AUTOSAR XML (schema 3.1.2)
package /Components/SWC_PFilFast
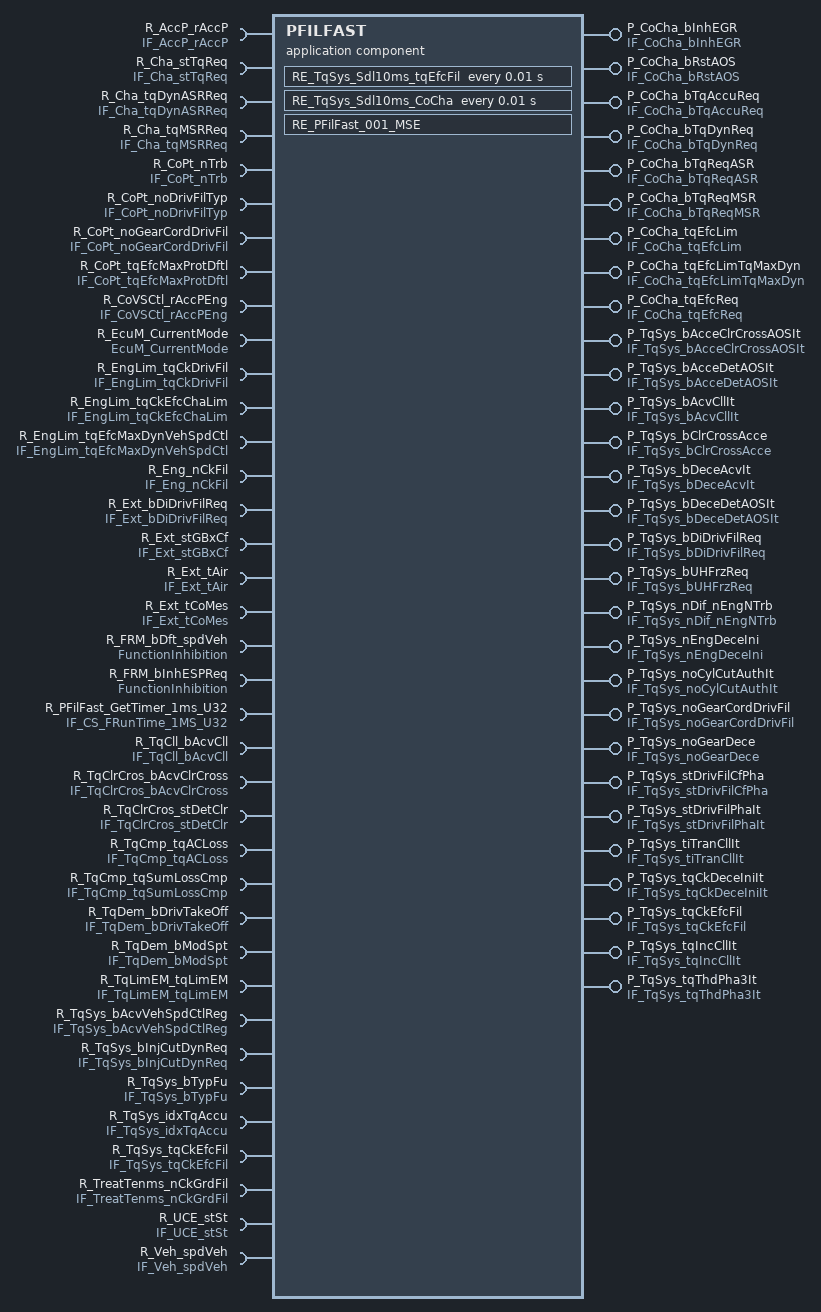
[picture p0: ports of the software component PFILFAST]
  application software component type PFILFAST  # PFilFast
    29 x provide port:
      P_CoCha_bInhEGR: unqueued-sender-com-spec{data-element=CoCha_bInhEGR, can-invalidate=false, init-value=ConstantValue}, provided-interface=IF_CoCha_bInhEGR  # Requirement: 01552_10_01267-PFilFast.I148(0)
      P_CoCha_bRstAOS: unqueued-sender-com-spec{data-element=CoCha_bRstAOS, can-invalidate=false, init-value=ConstantValue1}, provided-interface=IF_CoCha_bRstAOS  # Requirement: 01552_10_01267-PFilFast.I149(0)
      P_CoCha_bTqAccuReq: unqueued-sender-com-spec{data-element=CoCha_bTqAccuReq, can-invalidate=false, init-value=ConstantValue3}, provided-interface=IF_CoCha_bTqAccuReq  # Requirement: 01552_10_01267-PFilFast.I150(0)
      P_CoCha_bTqDynReq: unqueued-sender-com-spec{data-element=CoCha_bTqDynReq, can-invalidate=false, init-value=ConstantValue5}, provided-interface=IF_CoCha_bTqDynReq  # Requirement: 01552_10_01267-PFilFast.I151(0)
      P_CoCha_bTqReqASR: unqueued-sender-com-spec{data-element=CoCha_bTqReqASR, can-invalidate=false, init-value=ConstantValue7}, provided-interface=IF_CoCha_bTqReqASR  # Requirement: 01552_10_01267-PFilFast.I152(0)
      P_CoCha_bTqReqMSR: unqueued-sender-com-spec{data-element=CoCha_bTqReqMSR, can-invalidate=false, init-value=ConstantValue9}, provided-interface=IF_CoCha_bTqReqMSR  # Requirement: 01552_10_01267-PFilFast.I153(0)
      P_CoCha_tqEfcLim: unqueued-sender-com-spec{data-element=CoCha_tqEfcLim, can-invalidate=false, init-value=ConstantValue11}, provided-interface=IF_CoCha_tqEfcLim  # Requirement: 01552_10_01267-PFilFast.I154(0)
      P_CoCha_tqEfcLimTqMaxDyn: unqueued-sender-com-spec{data-element=CoCha_tqEfcLimTqMaxDyn, can-invalidate=false, init-value=ConstantValue13}, provided-interface=IF_CoCha_tqEfcLimTqMaxDyn  # Requirement: 01552_10_01267-PFilFast.I146(0)
      P_CoCha_tqEfcReq: unqueued-sender-com-spec{data-element=CoCha_tqEfcReq, can-invalidate=false, init-value=ConstantValue15}, provided-interface=IF_CoCha_tqEfcReq  # Requirement: 01552_10_01267-PFilFast.I147(0)
      P_TqSys_bAcceClrCrossAOSIt: unqueued-sender-com-spec{data-element=TqSys_bAcceClrCrossAOSIt, can-invalidate=false, init-value=ConstantValue17}, provided-interface=IF_TqSys_bAcceClrCrossAOSIt  # Requirement: 01552_10_01267-PFilFast.I102(0)
      P_TqSys_bAcceDetAOSIt: unqueued-sender-com-spec{data-element=TqSys_bAcceDetAOSIt, can-invalidate=false, init-value=ConstantValue19}, provided-interface=IF_TqSys_bAcceDetAOSIt  # Requirement: 01552_10_01267-PFilFast.I103(0)
      P_TqSys_bAcvCllIt: unqueued-sender-com-spec{data-element=TqSys_bAcvCllIt, can-invalidate=false, init-value=ConstantValue21}, provided-interface=IF_TqSys_bAcvCllIt  # Requirement: 01552_10_01267-PFilFast.I104(0)
      P_TqSys_bClrCrossAcce: unqueued-sender-com-spec{data-element=TqSys_bClrCrossAcce, can-invalidate=false, init-value=ConstantValue23}, provided-interface=IF_TqSys_bClrCrossAcce  # Requirement: 01552_10_01267-PFilFast.I105(0)
      P_TqSys_bDeceAcvIt: unqueued-sender-com-spec{data-element=TqSys_bDeceAcvIt, can-invalidate=false, init-value=ConstantValue25}, provided-interface=IF_TqSys_bDeceAcvIt  # Requirement: 01552_10_01267-PFilFast.I106(0)
      P_TqSys_bDeceDetAOSIt: unqueued-sender-com-spec{data-element=TqSys_bDeceDetAOSIt, can-invalidate=false, init-value=ConstantValue27}, provided-interface=IF_TqSys_bDeceDetAOSIt  # Requirement: 01552_10_01267-PFilFast.I107(0)
      P_TqSys_bDiDrivFilReq: unqueued-sender-com-spec{data-element=TqSys_bDiDrivFilReq, can-invalidate=false, init-value=ConstantValue29}, provided-interface=IF_TqSys_bDiDrivFilReq  # Requirement: 01552_10_01267-PFilFast.I100(0)
      P_TqSys_bUHFrzReq: unqueued-sender-com-spec{data-element=TqSys_bUHFrzReq, can-invalidate=false, init-value=ConstantValue31}, provided-interface=IF_TqSys_bUHFrzReq  # Requirement: 01552_10_01267-PFilFast.I108(0)
      P_TqSys_nDif_nEngNTrb: unqueued-sender-com-spec{data-element=TqSys_nDif_nEngNTrb, can-invalidate=false, init-value=ConstantValue33}, provided-interface=IF_TqSys_nDif_nEngNTrb  # Requirement: 01552_10_01267-PFilFast.I109(0)
      P_TqSys_nEngDeceIni: unqueued-sender-com-spec{data-element=TqSys_nEngDeceIni, can-invalidate=false, init-value=ConstantValue35}, provided-interface=IF_TqSys_nEngDeceIni  # Requirement: 01552_10_01267-PFilFast.I101(0)
      P_TqSys_noCylCutAuthIt: unqueued-sender-com-spec{data-element=TqSys_noCylCutAuthIt, can-invalidate=false, init-value=ConstantValue37}, provided-interface=IF_TqSys_noCylCutAuthIt  # Requirement: 01552_10_01267-PFilFast.I110(0)
      P_TqSys_noGearCordDrivFil: unqueued-sender-com-spec{data-element=TqSys_noGearCordDrivFil, can-invalidate=false, init-value=ConstantValue39}, provided-interface=IF_TqSys_noGearCordDrivFil  # Requirement: 01552_10_01267-PFilFast.I111(0)
      P_TqSys_noGearDece: unqueued-sender-com-spec{data-element=TqSys_noGearDece, can-invalidate=false, init-value=ConstantValue41}, provided-interface=IF_TqSys_noGearDece  # Requirement: 01552_10_01267-PFilFast.I112(0)
      P_TqSys_stDrivFilCfPha: unqueued-sender-com-spec{data-element=TqSys_stDrivFilCfPha, can-invalidate=false, init-value=ConstantValue43}, provided-interface=IF_TqSys_stDrivFilCfPha  # Requirement: 01552_10_01267-PFilFast.I113(0)
      P_TqSys_stDrivFilPhaIt: unqueued-sender-com-spec{data-element=TqSys_stDrivFilPhaIt, can-invalidate=false, init-value=ConstantValue45}, provided-interface=IF_TqSys_stDrivFilPhaIt  # Requirement: 01552_10_01267-PFilFast.I114(0)
      P_TqSys_tiTranCllIt: unqueued-sender-com-spec{data-element=TqSys_tiTranCllIt, can-invalidate=false, init-value=ConstantValue47}, provided-interface=IF_TqSys_tiTranCllIt  # Requirement: 01552_10_01267-PFilFast.I115(0)
      P_TqSys_tqCkDeceIniIt: unqueued-sender-com-spec{data-element=TqSys_tqCkDeceIniIt, can-invalidate=false, init-value=ConstantValue49}, provided-interface=IF_TqSys_tqCkDeceIniIt  # Requirement: 01552_10_01267-PFilFast.I116(0)
      P_TqSys_tqCkEfcFil: unqueued-sender-com-spec{data-element=TqSys_tqCkEfcFil, can-invalidate=false, init-value=ConstantValue51}, provided-interface=IF_TqSys_tqCkEfcFil  # Requirement: 01552_10_01267-PFilFast.I117(0)
      P_TqSys_tqIncCllIt: unqueued-sender-com-spec{data-element=TqSys_tqIncCllIt, can-invalidate=false, init-value=ConstantValue53}, provided-interface=IF_TqSys_tqIncCllIt  # Requirement: 01552_10_01267-PFilFast.I118(0)
      P_TqSys_tqThdPha3It: unqueued-sender-com-spec{data-element=TqSys_tqThdPha3It, can-invalidate=false, init-value=ConstantValue55}, provided-interface=IF_TqSys_tqThdPha3It  # Requirement: 01552_10_01267-PFilFast.I119(0)
    37 x require port:
      R_AccP_rAccP: unqueued-receiver-com-spec{data-element=AccP_rAccP, init-value=ConstantValue57, resync-time=0}, required-interface=IF_AccP_rAccP  # Requirement: 01552_10_01267-PFilFast.I120(0)
      R_Cha_stTqReq: unqueued-receiver-com-spec{data-element=Cha_stTqReq, init-value=ConstantValue59, resync-time=0}, required-interface=IF_Cha_stTqReq  # Requirement: 01552_10_01267-PFilFast.I155(0)
      R_Cha_tqDynASRReq: unqueued-receiver-com-spec{data-element=Cha_tqDynASRReq, init-value=ConstantValue61, resync-time=0}, required-interface=IF_Cha_tqDynASRReq  # Requirement: 01552_10_01267-PFilFast.I121(0)
      R_Cha_tqMSRReq: unqueued-receiver-com-spec{data-element=Cha_tqMSRReq, init-value=ConstantValue63, resync-time=0}, required-interface=IF_Cha_tqMSRReq  # Requirement: 01552_10_01267-PFilFast.I156(0)
      R_CoPt_nTrb: unqueued-receiver-com-spec{data-element=CoPt_nTrb, init-value=ConstantValue65, resync-time=0}, required-interface=IF_CoPt_nTrb  # Requirement: 01552_10_01267-PFilFast.I124(0)
      R_CoPt_noDrivFilTyp: unqueued-receiver-com-spec{data-element=CoPt_noDrivFilTyp, init-value=ConstantValue67, resync-time=0}, required-interface=IF_CoPt_noDrivFilTyp  # Requirement: 01552_10_01267-PFilFast.I122(0)
      R_CoPt_noGearCordDrivFil: unqueued-receiver-com-spec{data-element=CoPt_noGearCordDrivFil, init-value=ConstantValue69, resync-time=0}, required-interface=IF_CoPt_noGearCordDrivFil  # Requirement: 01552_10_01267-PFilFast.I123(0)
      R_CoPt_tqEfcMaxProtDftl: unqueued-receiver-com-spec{data-element=CoPt_tqEfcMaxProtDftl, init-value=ConstantValue71, resync-time=0}, required-interface=IF_CoPt_tqEfcMaxProtDftl  # Requirement: 01552_10_01267-PFilFast.I157(0)
      R_CoVSCtl_rAccPEng: unqueued-receiver-com-spec{data-element=CoVSCtl_rAccPEng, init-value=ConstantValue73, resync-time=0}, required-interface=IF_CoVSCtl_rAccPEng  # Requirement: 01552_10_01267-PFilFast.I125(0)
      R_EcuM_CurrentMode: required-interface=EcuM_CurrentMode  # Requirement: 01552_09_00532-SSTG-C007(0)
      R_EngLim_tqCkDrivFil: unqueued-receiver-com-spec{data-element=EngLim_tqCkDrivFil, init-value=ConstantValue75, resync-time=0}, required-interface=IF_EngLim_tqCkDrivFil  # Requirement: 01552_10_01267-PFilFast.I127(0)
      R_EngLim_tqCkEfcChaLim: unqueued-receiver-com-spec{data-element=EngLim_tqCkEfcChaLim, init-value=ConstantValue77, resync-time=0}, required-interface=IF_EngLim_tqCkEfcChaLim  # Requirement: 01552_10_01267-PFilFast.I158(0)
      R_EngLim_tqEfcMaxDynVehSpdCtl: unqueued-receiver-com-spec{data-element=EngLim_tqEfcMaxDynVehSpdCtl, init-value=ConstantValue79, resync-time=0}, required-interface=IF_EngLim_tqEfcMaxDynVehSpdCtl  # Requirement: 01552_10_01267-PFilFast.I159(0)
      R_Eng_nCkFil: unqueued-receiver-com-spec{data-element=Eng_nCkFil, init-value=ConstantValue81, resync-time=0}, required-interface=IF_Eng_nCkFil  # Requirement: 01552_10_01267-PFilFast.I126(0)
      R_Ext_bDiDrivFilReq: unqueued-receiver-com-spec{data-element=Ext_bDiDrivFilReq, init-value=ConstantValue83, resync-time=0}, required-interface=IF_Ext_bDiDrivFilReq  # Requirement: 01552_10_01267-PFilFast.I128(0)
      R_Ext_stGBxCf: unqueued-receiver-com-spec{data-element=Ext_stGBxCf, init-value=ConstantValue85, resync-time=0}, required-interface=IF_Ext_stGBxCf  # Requirement: 01552_10_01267-PFilFast.I129(0)
      R_Ext_tAir: unqueued-receiver-com-spec{data-element=Ext_tAir, init-value=ConstantValue87, resync-time=0}, required-interface=IF_Ext_tAir  # Requirement: 01552_10_01267-PFilFast.I130(0)
      R_Ext_tCoMes: unqueued-receiver-com-spec{data-element=Ext_tCoMes, init-value=ConstantValue89, resync-time=0}, required-interface=IF_Ext_tCoMes  # Requirement: 01552_10_01267-PFilFast.I131(0)
      R_FRM_bDft_spdVeh: required-interface=FunctionInhibition  # Requirement: 01552_10_01267-PFilFast.I700(0)
      R_FRM_bInhESPReq: required-interface=FunctionInhibition  # Requirement: 01552_10_01267-PFilFast.I701(0)
      R_PFilFast_GetTimer_1ms_U32: required-interface=IF_CS_FRunTime_1MS_U32
      R_TqCll_bAcvCll: unqueued-receiver-com-spec{data-element=TqCll_bAcvCll, init-value=ConstantValue91, resync-time=0}, required-interface=IF_TqCll_bAcvCll  # Requirement: 01552_10_01267-PFilFast.I132(0)
      R_TqClrCros_bAcvClrCross: unqueued-receiver-com-spec{data-element=TqClrCros_bAcvClrCross, init-value=ConstantValue93, resync-time=0}, required-interface=IF_TqClrCros_bAcvClrCross  # Requirement: 01552_10_01267-PFilFast.I133(0)
      R_TqClrCros_stDetClr: unqueued-receiver-com-spec{data-element=TqClrCros_stDetClr, init-value=ConstantValue95, resync-time=0}, required-interface=IF_TqClrCros_stDetClr  # Requirement: 01552_10_01267-PFilFast.I134(0)
      R_TqCmp_tqACLoss: unqueued-receiver-com-spec{data-element=TqCmp_tqACLoss, init-value=ConstantValue97, resync-time=0}, required-interface=IF_TqCmp_tqACLoss  # Requirement: 01552_10_01267-PFilFast.I135(0)
      R_TqCmp_tqSumLossCmp: unqueued-receiver-com-spec{data-element=TqCmp_tqSumLossCmp, init-value=ConstantValue99, resync-time=0}, required-interface=IF_TqCmp_tqSumLossCmp  # Requirement: 01552_10_01267-PFilFast.I136(0)
      R_TqDem_bDrivTakeOff: unqueued-receiver-com-spec{data-element=TqDem_bDrivTakeOff, init-value=ConstantValue101, resync-time=0}, required-interface=IF_TqDem_bDrivTakeOff  # Requirement: 01552_10_01267-PFilFast.I137(0)
      R_TqDem_bModSpt: unqueued-receiver-com-spec{data-element=TqDem_bModSpt, init-value=ConstantValue103, resync-time=0}, required-interface=IF_TqDem_bModSpt  # Requirement: 01552_10_01267-PFilFast.I138(0)
      R_TqLimEM_tqLimEM: unqueued-receiver-com-spec{data-element=TqLimEM_tqLimEM, init-value=ConstantValue105, resync-time=0}, required-interface=IF_TqLimEM_tqLimEM  # Requirement: 01552_10_01267-PFilFast.I139(0)
      R_TqSys_bAcvVehSpdCtlReg: unqueued-receiver-com-spec{data-element=TqSys_bAcvVehSpdCtlReg, init-value=ConstantValue107, resync-time=0}, required-interface=IF_TqSys_bAcvVehSpdCtlReg  # Requirement: 01552_10_01267-PFilFast.I140(0)
      R_TqSys_bInjCutDynReq: unqueued-receiver-com-spec{data-element=TqSys_bInjCutDynReq, init-value=ConstantValue109, resync-time=0}, required-interface=IF_TqSys_bInjCutDynReq  # Requirement: 01552_10_01267-PFilFast.I141(0)
      R_TqSys_bTypFu: unqueued-receiver-com-spec{data-element=TqSys_bTypFu, init-value=ConstantValue111, resync-time=0}, required-interface=IF_TqSys_bTypFu  # Requirement: 01552_10_01267-PFilFast.I142(0)
      R_TqSys_idxTqAccu: unqueued-receiver-com-spec{data-element=TqSys_idxTqAccu, init-value=ConstantValue113, resync-time=0}, required-interface=IF_TqSys_idxTqAccu  # Requirement: 01552_10_01267-PFilFast.I143(0)
      R_TqSys_tqCkEfcFil: unqueued-receiver-com-spec{data-element=TqSys_tqCkEfcFil, init-value=ConstantValue115, resync-time=0}, required-interface=IF_TqSys_tqCkEfcFil  # Requirement: 01552_10_01267-PFilFast.I160(0)
      R_TreatTenms_nCkGrdFil: unqueued-receiver-com-spec{data-element=TreatTenms_nCkGrdFil, init-value=ConstantValue117, resync-time=0}, required-interface=IF_TreatTenms_nCkGrdFil  # Requirement: 01552_10_01267-PFilFast.I144(0)
      R_UCE_stSt: required-interface=IF_UCE_stSt  # Requirement: 01552_09_00532-SSTG-C011(0)
      R_Veh_spdVeh: unqueued-receiver-com-spec{data-element=Veh_spdVeh, init-value=ConstantValue119, resync-time=0}, required-interface=IF_Veh_spdVeh  # Requirement: 01552_10_01267-PFilFast.I145(0)
  61 x constant specification:
    ConstantValue
      value:
        boolean literal ConstantValue: type=DT_CoCha_bInhEGR, value=false
    ConstantValue1
      value:
        boolean literal ConstantValue1: type=DT_CoCha_bRstAOS, value=false
    ConstantValue101
      value:
        boolean literal ConstantValue101: type=DT_TqDem_bDrivTakeOff, value=false
    ConstantValue103
      value:
        boolean literal ConstantValue103: type=DT_TqDem_bModSpt, value=false
    ConstantValue105
      value:
        integer literal ConstantValue105: type=DT_TqLimEM_tqLimEM, value=0
    ConstantValue107
      value:
        boolean literal ConstantValue107: type=DT_TqSys_bAcvVehSpdCtlReg, value=false
    ConstantValue109
      value:
        boolean literal ConstantValue109: type=DT_TqSys_bInjCutDynReq, value=false
    ConstantValue11
      value:
        integer literal ConstantValue11: type=DT_CoCha_tqEfcLim, value=0
    ConstantValue111
      value:
        boolean literal ConstantValue111: type=DT_TqSys_bTypFu, value=false
    ConstantValue113
      value:
        integer literal ConstantValue113: type=DT_TqSys_idxTqAccu, value=1
    ConstantValue115
      value:
        integer literal ConstantValue115: type=DT_TqSys_tqCkEfcFil, value=0
    ConstantValue117
      value:
        integer literal ConstantValue117: type=DT_TreatTenms_nCkGrdFil, value=0
    ConstantValue119
      value:
        integer literal ConstantValue119: type=DT_Veh_spdVeh, value=0
    ConstantValue13
      value:
        integer literal ConstantValue13: type=DT_CoCha_tqEfcLimTqMaxDyn, value=0
    ConstantValue15
      value:
        integer literal ConstantValue15: type=DT_CoCha_tqEfcReq, value=0
    ConstantValue17
      value:
        boolean literal ConstantValue17: type=DT_TqSys_bAcceClrCrossAOSIt, value=false
    ConstantValue19
      value:
        boolean literal ConstantValue19: type=DT_TqSys_bAcceDetAOSIt, value=false
    ConstantValue21
      value:
        boolean literal ConstantValue21: type=DT_TqSys_bAcvCllIt, value=false
    ConstantValue23
      value:
        boolean literal ConstantValue23: type=DT_TqSys_bClrCrossAcce, value=false
    ConstantValue25
      value:
        boolean literal ConstantValue25: type=DT_TqSys_bDeceAcvIt, value=false
    ConstantValue27
      value:
        boolean literal ConstantValue27: type=DT_TqSys_bDeceDetAOSIt, value=false
    ConstantValue29
      value:
        boolean literal ConstantValue29: type=DT_TqSys_bDiDrivFilReq, value=false
    ConstantValue3
      value:
        boolean literal ConstantValue3: type=DT_CoCha_bTqAccuReq, value=false
    ConstantValue31
      value:
        boolean literal ConstantValue31: type=DT_TqSys_bUHFrzReq, value=false
    ConstantValue33
      value:
        integer literal ConstantValue33: type=DT_TqSys_nDif_nEngNTrb, value=0
    ConstantValue35
      value:
        integer literal ConstantValue35: type=DT_TqSys_nEngDeceIni, value=0
    ConstantValue37
      value:
        integer literal ConstantValue37: type=DT_TqSys_noCylCutAuthIt, value=0
    ConstantValue39
      value:
        integer literal ConstantValue39: type=DT_TqSys_noGearCordDrivFil, value=0
    ConstantValue41
      value:
        integer literal ConstantValue41: type=DT_TqSys_noGearDece, value=0
    ConstantValue43
      value:
        integer literal ConstantValue43: type=DT_TqSys_stDrivFilCfPha, value=0
    ConstantValue45
      value:
        integer literal ConstantValue45: type=DT_TqSys_stDrivFilPhaIt, value=0
    ConstantValue47
      value:
        integer literal ConstantValue47: type=DT_TqSys_tiTranCllIt, value=0
    ConstantValue49
      value:
        integer literal ConstantValue49: type=DT_TqSys_tqCkDeceIniIt, value=0
    ConstantValue5
      value:
        boolean literal ConstantValue5: type=DT_CoCha_bTqDynReq, value=false
    ConstantValue51
      value:
        integer literal ConstantValue51: type=DT_TqSys_tqCkEfcFil, value=0
    ConstantValue53
      value:
        integer literal ConstantValue53: type=DT_TqSys_tqIncCllIt, value=0
    ConstantValue55
      value:
        integer literal ConstantValue55: type=DT_TqSys_tqThdPha3It, value=0
    ConstantValue57
      value:
        integer literal ConstantValue57: type=DT_AccP_rAccP, value=0
    ConstantValue59
      value:
        integer literal ConstantValue59: type=DT_Cha_stTqReq, value=0
    ConstantValue61
      value:
        integer literal ConstantValue61: type=DT_Cha_tqDynASRReq, value=0
    ConstantValue63
      value:
        integer literal ConstantValue63: type=DT_Cha_tqMSRReq, value=0
    ConstantValue65
      value:
        integer literal ConstantValue65: type=DT_CoPt_nTrb, value=0
    ConstantValue67
      value:
        integer literal ConstantValue67: type=DT_CoPt_noDrivFilTyp, value=0
    ConstantValue69
      value:
        integer literal ConstantValue69: type=DT_CoPt_noGearCordDrivFil, value=0
    ConstantValue7
      value:
        boolean literal ConstantValue7: type=DT_CoCha_bTqReqASR, value=false
    ConstantValue71
      value:
        integer literal ConstantValue71: type=DT_CoPt_tqEfcMaxProtDftl, value=32000
    ConstantValue73
      value:
        integer literal ConstantValue73: type=DT_CoVSCtl_rAccPEng, value=0
    ConstantValue75
      value:
        integer literal ConstantValue75: type=DT_EngLim_tqCkDrivFil, value=32000
    ConstantValue77
      value:
        integer literal ConstantValue77: type=DT_EngLim_tqCkEfcChaLim, value=32000
    ConstantValue79
      value:
        integer literal ConstantValue79: type=DT_EngLim_tqEfcMaxDynVehSpdCtl, value=32000
    ConstantValue81
      value:
        integer literal ConstantValue81: type=DT_Eng_nCkFil, value=0
    ConstantValue83
      value:
        boolean literal ConstantValue83: type=DT_Ext_bDiDrivFilReq, value=false
    ConstantValue85
      value:
        integer literal ConstantValue85: type=DT_Ext_stGBxCf, value=0
    ConstantValue87
      value:
        integer literal ConstantValue87: type=DT_Ext_tAir, value=20
    ConstantValue89
      value:
        integer literal ConstantValue89: type=DT_Ext_tCoMes, value=20
    ConstantValue9
      value:
        boolean literal ConstantValue9: type=DT_CoCha_bTqReqMSR, value=false
    ConstantValue91
      value:
        boolean literal ConstantValue91: type=DT_TqCll_bAcvCll, value=false
    ConstantValue93
      value:
        boolean literal ConstantValue93: type=DT_TqClrCros_bAcvClrCross, value=false
    ConstantValue95
      value:
        integer literal ConstantValue95: type=DT_TqClrCros_stDetClr, value=0
    ConstantValue97
      value:
        integer literal ConstantValue97: type=DT_TqCmp_tqACLoss, value=0
    ConstantValue99
      value:
        integer literal ConstantValue99: type=DT_TqCmp_tqSumLossCmp, value=0
  internal behavior IB_PFilFast: component=PFILFAST
    timing event EV_TqSys_Sdl10ms_tqEfcFil: mode-dependency=dependent-on-mode=[R_UCE_stSt.RCD_Mode.COM_LATCH, R_UCE_stSt.RCD_Mode.INTERNAL_PARTIAL_WAKEUP, R_UCE_stSt.RCD_Mode.INTERNAL_PARTIAL_WAKEUP_APC, R_UCE_stSt.RCD_Mode.PARTIAL_WAKEUP, R_UCE_stSt.RCD_Mode.SHUTDOWN_PREPARATION, R_UCE_stSt.RCD_Mode.SHUTDOWN_PREPARATION_APC, R_UCE_stSt.RCD_Mode.TRANSITORY], start-on-event=RE_TqSys_Sdl10ms_tqEfcFil, period=0.01
    timing event EV_TqSys_Sdl10ms_CoCha: mode-dependency=dependent-on-mode=[R_UCE_stSt.RCD_Mode.COM_LATCH, R_UCE_stSt.RCD_Mode.INTERNAL_PARTIAL_WAKEUP, R_UCE_stSt.RCD_Mode.INTERNAL_PARTIAL_WAKEUP_APC, R_UCE_stSt.RCD_Mode.PARTIAL_WAKEUP, R_UCE_stSt.RCD_Mode.SHUTDOWN_PREPARATION, R_UCE_stSt.RCD_Mode.SHUTDOWN_PREPARATION_APC, R_UCE_stSt.RCD_Mode.TRANSITORY], start-on-event=RE_TqSys_Sdl10ms_CoCha, period=0.01
    mode switch event EV_PFilFast_001_MSE: start-on-event=RE_PFilFast_001_MSE, activation=ENTRY, mode=R_EcuM_CurrentMode.currentMode.RUN
    runnable RE_TqSys_Sdl10ms_CoCha
      7 x data receive point:
        dr_EngLim_tqCkEfcChaLim: data-element=R_EngLim_tqCkEfcChaLim.EngLim_tqCkEfcChaLim
        dr_Cha_tqMSRReq: data-element=R_Cha_tqMSRReq.Cha_tqMSRReq
        dr_Cha_tqDynASRReq: data-element=R_Cha_tqDynASRReq.Cha_tqDynASRReq
        dr_TqSys_tqCkEfcFil: data-element=R_TqSys_tqCkEfcFil.TqSys_tqCkEfcFil
        dr_Cha_stTqReq: data-element=R_Cha_stTqReq.Cha_stTqReq
        dr_CoPt_tqEfcMaxProtDftl: data-element=R_CoPt_tqEfcMaxProtDftl.CoPt_tqEfcMaxProtDftl
        dr_EngLim_tqEfcMaxDynVehSpdCtl: data-element=R_EngLim_tqEfcMaxDynVehSpdCtl.EngLim_tqEfcMaxDynVehSpdCtl
      9 x data send point:
        ds_CoCha_tqEfcLim: data-element=P_CoCha_tqEfcLim.CoCha_tqEfcLim
        ds_CoCha_bRstAOS: data-element=P_CoCha_bRstAOS.CoCha_bRstAOS
        ds_CoCha_bTqAccuReq: data-element=P_CoCha_bTqAccuReq.CoCha_bTqAccuReq
        ds_CoCha_bTqReqMSR: data-element=P_CoCha_bTqReqMSR.CoCha_bTqReqMSR
        ds_CoCha_bTqReqASR: data-element=P_CoCha_bTqReqASR.CoCha_bTqReqASR
        ds_CoCha_bInhEGR: data-element=P_CoCha_bInhEGR.CoCha_bInhEGR
        ds_CoCha_tqEfcLimTqMaxDyn: data-element=P_CoCha_tqEfcLimTqMaxDyn.CoCha_tqEfcLimTqMaxDyn
        ds_CoCha_tqEfcReq: data-element=P_CoCha_tqEfcReq.CoCha_tqEfcReq
        ds_CoCha_bTqDynReq: data-element=P_CoCha_bTqDynReq.CoCha_bTqDynReq
      sync call ssp_FRM_bInhESPReq: operation=R_FRM_bInhESPReq.GetFunctionPermission
      sync call ssp_GetTimer_1ms_U32: operation=R_PFilFast_GetTimer_1ms_U32.GetTimer_1ms_U32
    runnable RE_PFilFast_001_MSE
      29 x data send point:
        ds_CoCha_bTqReqMSR: data-element=P_CoCha_bTqReqMSR.CoCha_bTqReqMSR
        ds_TqSys_noCylCutAuthIt: data-element=P_TqSys_noCylCutAuthIt.TqSys_noCylCutAuthIt
        ds_TqSys_tqIncCllIt: data-element=P_TqSys_tqIncCllIt.TqSys_tqIncCllIt
        ds_TqSys_nEngDeceIni: data-element=P_TqSys_nEngDeceIni.TqSys_nEngDeceIni
        ds_TqSys_stDrivFilCfPha: data-element=P_TqSys_stDrivFilCfPha.TqSys_stDrivFilCfPha
        ds_CoCha_bTqAccuReq: data-element=P_CoCha_bTqAccuReq.CoCha_bTqAccuReq
        ds_CoCha_bTqDynReq: data-element=P_CoCha_bTqDynReq.CoCha_bTqDynReq
        ds_TqSys_bUHFrzReq: data-element=P_TqSys_bUHFrzReq.TqSys_bUHFrzReq
        ds_TqSys_nDif_nEngNTrb: data-element=P_TqSys_nDif_nEngNTrb.TqSys_nDif_nEngNTrb
        ds_TqSys_stDrivFilPhaIt: data-element=P_TqSys_stDrivFilPhaIt.TqSys_stDrivFilPhaIt
        ds_TqSys_bDeceAcvIt: data-element=P_TqSys_bDeceAcvIt.TqSys_bDeceAcvIt
        ds_TqSys_noGearCordDrivFil: data-element=P_TqSys_noGearCordDrivFil.TqSys_noGearCordDrivFil
        ds_CoCha_tqEfcReq: data-element=P_CoCha_tqEfcReq.CoCha_tqEfcReq
        ds_TqSys_tiTranCllIt: data-element=P_TqSys_tiTranCllIt.TqSys_tiTranCllIt
        ds_TqSys_bDeceDetAOSIt: data-element=P_TqSys_bDeceDetAOSIt.TqSys_bDeceDetAOSIt
        ds_TqSys_noGearDece: data-element=P_TqSys_noGearDece.TqSys_noGearDece
        ds_CoCha_bInhEGR: data-element=P_CoCha_bInhEGR.CoCha_bInhEGR
        ds_TqSys_tqCkDeceIniIt: data-element=P_TqSys_tqCkDeceIniIt.TqSys_tqCkDeceIniIt
        ds_CoCha_bTqReqASR: data-element=P_CoCha_bTqReqASR.CoCha_bTqReqASR
        ds_TqSys_tqCkEfcFil: data-element=P_TqSys_tqCkEfcFil.TqSys_tqCkEfcFil
        ds_CoCha_tqEfcLimTqMaxDyn: data-element=P_CoCha_tqEfcLimTqMaxDyn.CoCha_tqEfcLimTqMaxDyn
        ds_TqSys_bAcceClrCrossAOSIt: data-element=P_TqSys_bAcceClrCrossAOSIt.TqSys_bAcceClrCrossAOSIt
        ds_TqSys_tqThdPha3It: data-element=P_TqSys_tqThdPha3It.TqSys_tqThdPha3It
        ds_TqSys_bAcvCllIt: data-element=P_TqSys_bAcvCllIt.TqSys_bAcvCllIt
        ds_CoCha_tqEfcLim: data-element=P_CoCha_tqEfcLim.CoCha_tqEfcLim
        ds_CoCha_bRstAOS: data-element=P_CoCha_bRstAOS.CoCha_bRstAOS
        ds_TqSys_bAcceDetAOSIt: data-element=P_TqSys_bAcceDetAOSIt.TqSys_bAcceDetAOSIt
        ds_TqSys_bDiDrivFilReq: data-element=P_TqSys_bDiDrivFilReq.TqSys_bDiDrivFilReq
        ds_TqSys_bClrCrossAcce: data-element=P_TqSys_bClrCrossAcce.TqSys_bClrCrossAcce
      sync call ssp_GetTimer_1ms_U32: operation=R_PFilFast_GetTimer_1ms_U32.GetTimer_1ms_U32
    runnable RE_TqSys_Sdl10ms_tqEfcFil
      26 x data receive point:
        dr_Ext_tAir: data-element=R_Ext_tAir.Ext_tAir
        dr_TqClrCros_bAcvClrCross: data-element=R_TqClrCros_bAcvClrCross.TqClrCros_bAcvClrCross
        dr_TqClrCros_stDetClr: data-element=R_TqClrCros_stDetClr.TqClrCros_stDetClr
        dr_TqSys_bTypFu: data-element=R_TqSys_bTypFu.TqSys_bTypFu
        dr_TqCmp_tqSumLossCmp: data-element=R_TqCmp_tqSumLossCmp.TqCmp_tqSumLossCmp
        dr_EngLim_tqCkDrivFil: data-element=R_EngLim_tqCkDrivFil.EngLim_tqCkDrivFil
        dr_AccP_rAccP: data-element=R_AccP_rAccP.AccP_rAccP
        dr_CoPt_noDrivFilTyp: data-element=R_CoPt_noDrivFilTyp.CoPt_noDrivFilTyp
        dr_Ext_stGBxCf: data-element=R_Ext_stGBxCf.Ext_stGBxCf
        dr_Ext_tCoMes: data-element=R_Ext_tCoMes.Ext_tCoMes
        dr_CoVSCtl_rAccPEng: data-element=R_CoVSCtl_rAccPEng.CoVSCtl_rAccPEng
        dr_Veh_spdVeh: data-element=R_Veh_spdVeh.Veh_spdVeh
        dr_TqSys_idxTqAccu: data-element=R_TqSys_idxTqAccu.TqSys_idxTqAccu
        dr_CoPt_noGearCordDrivFil: data-element=R_CoPt_noGearCordDrivFil.CoPt_noGearCordDrivFil
        dr_TqDem_bDrivTakeOff: data-element=R_TqDem_bDrivTakeOff.TqDem_bDrivTakeOff
        dr_Ext_bDiDrivFilReq: data-element=R_Ext_bDiDrivFilReq.Ext_bDiDrivFilReq
        dr_TqCmp_tqACLoss: data-element=R_TqCmp_tqACLoss.TqCmp_tqACLoss
        dr_TqSys_bInjCutDynReq: data-element=R_TqSys_bInjCutDynReq.TqSys_bInjCutDynReq
        dr_TqCll_bAcvCll: data-element=R_TqCll_bAcvCll.TqCll_bAcvCll
        dr_CoPt_nTrb: data-element=R_CoPt_nTrb.CoPt_nTrb
        dr_TreatTenms_nCkGrdFil: data-element=R_TreatTenms_nCkGrdFil.TreatTenms_nCkGrdFil
        dr_TqDem_bModSpt: data-element=R_TqDem_bModSpt.TqDem_bModSpt
        dr_TqSys_bAcvVehSpdCtlReg: data-element=R_TqSys_bAcvVehSpdCtlReg.TqSys_bAcvVehSpdCtlReg
        dr_Cha_tqDynASRReq: data-element=R_Cha_tqDynASRReq.Cha_tqDynASRReq
        dr_Eng_nCkFil: data-element=R_Eng_nCkFil.Eng_nCkFil
        dr_TqLimEM_tqLimEM: data-element=R_TqLimEM_tqLimEM.TqLimEM_tqLimEM
      20 x data send point:
        ds_TqSys_noGearDece: data-element=P_TqSys_noGearDece.TqSys_noGearDece
        ds_TqSys_tqCkDeceIniIt: data-element=P_TqSys_tqCkDeceIniIt.TqSys_tqCkDeceIniIt
        ds_TqSys_bDiDrivFilReq: data-element=P_TqSys_bDiDrivFilReq.TqSys_bDiDrivFilReq
        ds_TqSys_bAcceDetAOSIt: data-element=P_TqSys_bAcceDetAOSIt.TqSys_bAcceDetAOSIt
        ds_TqSys_bUHFrzReq: data-element=P_TqSys_bUHFrzReq.TqSys_bUHFrzReq
        ds_TqSys_bClrCrossAcce: data-element=P_TqSys_bClrCrossAcce.TqSys_bClrCrossAcce
        ds_TqSys_stDrivFilCfPha: data-element=P_TqSys_stDrivFilCfPha.TqSys_stDrivFilCfPha
        ds_TqSys_bDeceDetAOSIt: data-element=P_TqSys_bDeceDetAOSIt.TqSys_bDeceDetAOSIt
        ds_TqSys_bAcceClrCrossAOSIt: data-element=P_TqSys_bAcceClrCrossAOSIt.TqSys_bAcceClrCrossAOSIt
        ds_TqSys_tqIncCllIt: data-element=P_TqSys_tqIncCllIt.TqSys_tqIncCllIt
        ds_TqSys_tqCkEfcFil: data-element=P_TqSys_tqCkEfcFil.TqSys_tqCkEfcFil
        ds_TqSys_nEngDeceIni: data-element=P_TqSys_nEngDeceIni.TqSys_nEngDeceIni
        ds_TqSys_tqThdPha3It: data-element=P_TqSys_tqThdPha3It.TqSys_tqThdPha3It
        ds_TqSys_bAcvCllIt: data-element=P_TqSys_bAcvCllIt.TqSys_bAcvCllIt
        ds_TqSys_nDif_nEngNTrb: data-element=P_TqSys_nDif_nEngNTrb.TqSys_nDif_nEngNTrb
        ds_TqSys_noCylCutAuthIt: data-element=P_TqSys_noCylCutAuthIt.TqSys_noCylCutAuthIt
        ds_TqSys_tiTranCllIt: data-element=P_TqSys_tiTranCllIt.TqSys_tiTranCllIt
        ds_TqSys_stDrivFilPhaIt: data-element=P_TqSys_stDrivFilPhaIt.TqSys_stDrivFilPhaIt
        ds_TqSys_bDeceAcvIt: data-element=P_TqSys_bDeceAcvIt.TqSys_bDeceAcvIt
        ds_TqSys_noGearCordDrivFil: data-element=P_TqSys_noGearCordDrivFil.TqSys_noGearCordDrivFil
      sync call ssp_FRM_bDft_spdVeh: operation=R_FRM_bDft_spdVeh.GetFunctionPermission
      sync call ssp_GetTimer_1ms_U32: operation=R_PFilFast_GetTimer_1ms_U32.GetTimer_1ms_U32
  swc implementation Imp_PFilFast: programming-language=C, behavior=IB_PFilFast
    code-descriptors:
      code CodeDescriptor: type=SRC
        13 x xfile:
          PFilFast_MemMap_h: url=PFilFast_MemMap.h
          PFILFAST_State_Machine_c: url=PFILFAST_State_Machine.c
          PFILFAST_Decel_Thres_Slew_c: url=PFILFAST_Decel_Thres_Slew.c
          PFILFAST_Acc_Conf1_c: url=PFILFAST_Acc_Conf1.c
          PFILFAST_Pre_Treat_c: url=PFILFAST_Pre_Treat.c
          PFILFAST_Coord_Esp_c: url=PFILFAST_Coord_Esp.c
          PFILFAST_Filt_Activ_c: url=PFILFAST_Filt_Activ.c
          PFILFAST_Scnd_Out_c: url=PFILFAST_Scnd_Out.c
          PFILFAST_Acc_Thres_Wght_c: url=PFILFAST_Acc_Thres_Wght.c
          PFilFast_c: url=PFilFast.c
          PFILFAST_Decel_Times_c: url=PFILFAST_Decel_Times.c
          PFilFast_h: url=PFilFast.h
          PFILFAST_Acc_Conf2_c: url=PFILFAST_Acc_Conf2.c
